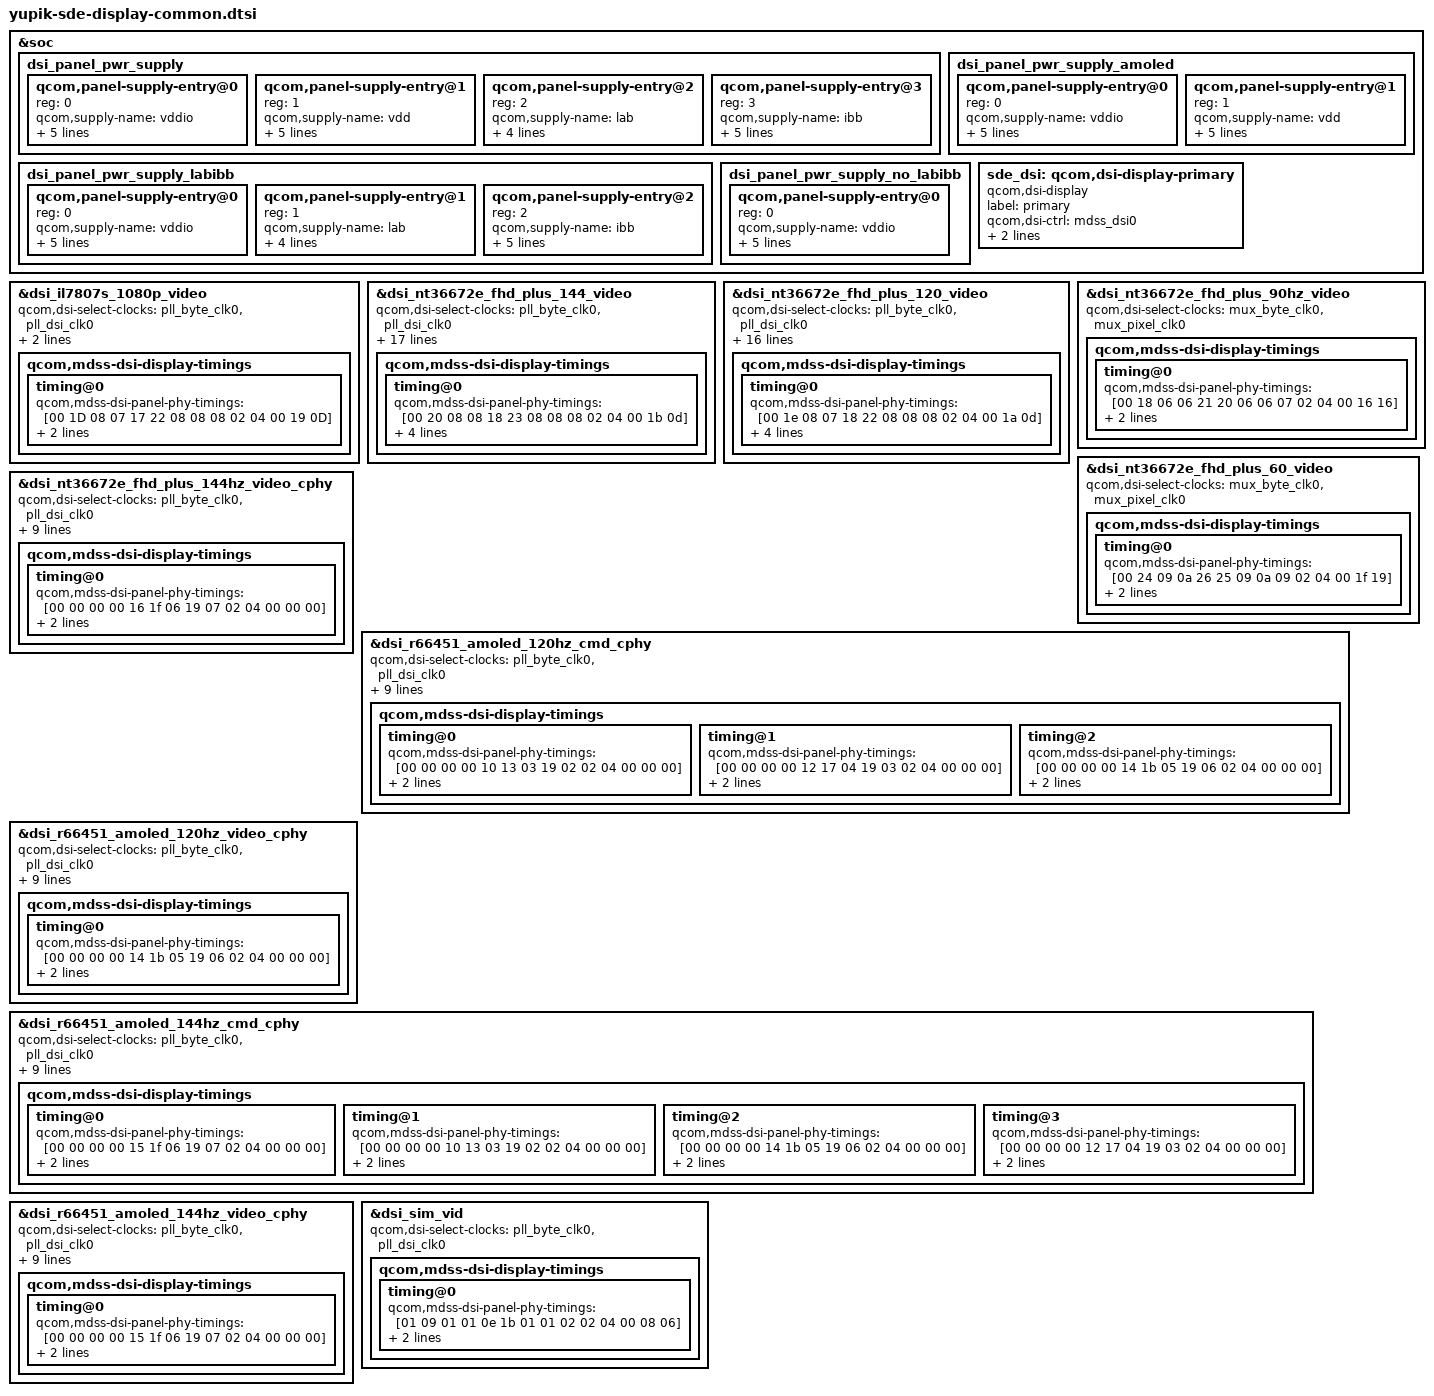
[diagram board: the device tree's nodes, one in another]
// SPDX-License-Identifier: BSD-3-Clause
/*
 * Copyright (c) Qualcomm Technologies, Inc. and/or its subsidiaries.
 */

#include "dsi-panel-nt36672e-fhd-plus-144-video.dtsi"
#include "dsi-panel-nt36672e-fhd-plus-120-video.dtsi"
#include "dsi-panel-nt36672e-fhd-plus-90hz-video.dtsi"
#include "dsi-panel-nt36672e-fhd-plus-60hz-video.dtsi"
#include "dsi-panel-nt36672e-fhd-plus-144hz-video-cphy.dtsi"
#include "dsi-panel-r66451-dsc-fhd-plus-60hz-cmd-cphy.dtsi"
#include "dsi-panel-r66451-dsc-fhd-plus-90hz-cmd-cphy.dtsi"
#include "dsi-panel-r66451-dsc-fhd-plus-120hz-cmd-cphy.dtsi"
#include "dsi-panel-r66451-dsc-fhd-plus-120hz-video-cphy.dtsi"
#include "dsi-panel-r66451-dsc-fhd-plus-144hz-cmd-cphy.dtsi"
#include "dsi-panel-r66451-dsc-fhd-plus-144hz-video-cphy.dtsi"
#include "dsi-panel-sim-video.dtsi"
#include "dsi-panel-ext-bridge-1080p.dtsi"
#include "dsi-panel-il7807s-1080p-video.dtsi"
#include "dsi-panel-ili9881p-720-video.dtsi"
#include "dsi-panel-ext-bridge-4k30p.dtsi"
#include <dt-bindings/clock/qcom,rpmh.h>
#include "yupik-sde-display-pinctrl.dtsi"

&soc {
	dsi_panel_pwr_supply: dsi_panel_pwr_supply {
		#address-cells = <1>;
		#size-cells = <0>;

		qcom,panel-supply-entry@0 {
			reg = <0>;
			qcom,supply-name = "vddio";
			qcom,supply-min-voltage = <1820000>;
			qcom,supply-max-voltage = <1820000>;
			qcom,supply-enable-load = <60700>;
			qcom,supply-disable-load = <80>;
			qcom,supply-post-on-sleep = <20>;
		};

		qcom,panel-supply-entry@1 {
			reg = <1>;
			qcom,supply-name = "vdd";
			qcom,supply-min-voltage = <3000000>;
			qcom,supply-max-voltage = <3000000>;
			qcom,supply-enable-load = <30000>;
			qcom,supply-disable-load = <0>;
			qcom,supply-post-on-sleep = <0>;
		};

		qcom,panel-supply-entry@2 {
			reg = <2>;
			qcom,supply-name = "lab";
			qcom,supply-min-voltage = <4600000>;
			qcom,supply-max-voltage = <6000000>;
			qcom,supply-enable-load = <0>;
			qcom,supply-disable-load = <0>;
		};

		qcom,panel-supply-entry@3 {
			reg = <3>;
			qcom,supply-name = "ibb";
			qcom,supply-min-voltage = <4600000>;
			qcom,supply-max-voltage = <6000000>;
			qcom,supply-enable-load = <0>;
			qcom,supply-disable-load = <0>;
			qcom,supply-post-on-sleep = <20>;
		};
	};

	dsi_panel_pwr_supply_labibb: dsi_panel_pwr_supply_labibb {
		#address-cells = <1>;
		#size-cells = <0>;

		qcom,panel-supply-entry@0 {
			reg = <0>;
			qcom,supply-name = "vddio";
			qcom,supply-min-voltage = <1800000>;
			qcom,supply-max-voltage = <1800000>;
			qcom,supply-enable-load = <62000>;
			qcom,supply-disable-load = <80>;
			qcom,supply-post-on-sleep = <20>;
		};

		qcom,panel-supply-entry@1 {
			reg = <1>;
			qcom,supply-name = "lab";
			qcom,supply-min-voltage = <5600000>;
			qcom,supply-max-voltage = <6000000>;
			qcom,supply-enable-load = <0>;
			qcom,supply-disable-load = <0>;
		};

		qcom,panel-supply-entry@2 {
			reg = <2>;
			qcom,supply-name = "ibb";
			qcom,supply-min-voltage = <5600000>;
			qcom,supply-max-voltage = <6000000>;
			qcom,supply-enable-load = <0>;
			qcom,supply-disable-load = <0>;
			qcom,supply-post-on-sleep = <20>;
		};
	};

	dsi_panel_pwr_supply_amoled: dsi_panel_pwr_supply_amoled {
		#address-cells = <1>;
		#size-cells = <0>;

		qcom,panel-supply-entry@0 {
			reg = <0>;
			qcom,supply-name = "vddio";
			qcom,supply-min-voltage = <1800000>;
			qcom,supply-max-voltage = <1800000>;
			qcom,supply-enable-load = <60700>;
			qcom,supply-disable-load = <80>;
			qcom,supply-post-on-sleep = <20>;
		};

		qcom,panel-supply-entry@1 {
			reg = <1>;
			qcom,supply-name = "vdd";
			qcom,supply-min-voltage = <3000000>;
			qcom,supply-max-voltage = <3000000>;
			qcom,supply-enable-load = <30000>;
			qcom,supply-disable-load = <0>;
			qcom,supply-post-on-sleep = <0>;
		};
	};

	dsi_panel_pwr_supply_no_labibb: dsi_panel_pwr_supply_no_labibb {
		#address-cells = <1>;
		#size-cells = <0>;

		qcom,panel-supply-entry@0 {
			reg = <0>;
			qcom,supply-name = "vddio";
			qcom,supply-min-voltage = <1800000>;
			qcom,supply-max-voltage = <1800000>;
			qcom,supply-enable-load = <62000>;
			qcom,supply-disable-load = <80>;
			qcom,supply-post-on-sleep = <20>;
		};
	};

	sde_dsi: qcom,dsi-display-primary {
		compatible = "qcom,dsi-display";
		label = "primary";

		qcom,dsi-ctrl = <&mdss_dsi0>;
		qcom,dsi-phy = <&mdss_dsi_phy0>;
		qcom,mdp = <&mdss_mdp>;
	};
};

&dsi_il7807s_1080p_video {
	qcom,dsi-select-clocks = "pll_byte_clk0", "pll_dsi_clk0";
	qcom,mdss-dsi-t-clk-post = <0x0d>;
	qcom,mdss-dsi-t-clk-pre = <0x19>;

	qcom,mdss-dsi-display-timings {
		timing@0{
			qcom,mdss-dsi-panel-phy-timings = [00 1D 08 07 17 22 08
			08 08 02 04 00 19 0D];
			qcom,display-topology = <1 0 1>;
			qcom,default-topology-index = <0>;
		};
	};
};

&dsi_nt36672e_fhd_plus_144_video{
        qcom,dsi-select-clocks = "pll_byte_clk0", "pll_dsi_clk0";

        qcom,qsync-enable;
        qcom,mdss-dsi-qsync-min-refresh-rate = <48>;

        qcom,dsi-supported-dfps-list = <144 120 60 48>;
        qcom,mdss-dsi-pan-enable-dynamic-fps;
        qcom,mdss-dsi-pan-fps-update = "dfps_immediate_porch_mode_vfp";

        qcom,dsi-dyn-clk-enable;
        qcom,dsi-dyn-clk-type = "constant-fps-adjust-vfp";

        qcom,esd-check-enabled;
        qcom,mdss-dsi-panel-status-check-mode = "reg_read";
        qcom,mdss-dsi-panel-status-command = [06 01 00 01 00 00 01 0a];
        qcom,mdss-dsi-panel-status-command-state = "dsi_lp_mode";
        qcom,mdss-dsi-panel-status-value = <0x9c>;
        qcom,mdss-dsi-panel-status-read-length = <1>;

        qcom,mdss-dsi-display-timings {
                timing@0 {
                        qcom,mdss-dsi-panel-phy-timings = [00 20 08 08 18 23 08
                                08 08 02 04 00 1b 0d];
                        qcom,display-topology = <1 1 1>;
                        qcom,default-topology-index = <0>;
                        qcom,dsi-dyn-clk-list = <957616128 950966016 954291072>;
                };
        };
};

&dsi_nt36672e_fhd_plus_120_video {
        qcom,dsi-select-clocks = "pll_byte_clk0", "pll_dsi_clk0";

        qcom,qsync-enable;
        qcom,mdss-dsi-qsync-min-refresh-rate = <48>;

        qcom,dsi-supported-dfps-list = <120 60 48>;
        qcom,mdss-dsi-pan-enable-dynamic-fps;
        qcom,mdss-dsi-pan-fps-update = "dfps_immediate_porch_mode_vfp";

        qcom,dsi-dyn-clk-enable;
        qcom,dsi-dyn-clk-type = "constant-fps-adjust-vfp";

        qcom,mdss-dsi-panel-status-check-mode = "reg_read";
        qcom,mdss-dsi-panel-status-command = [06 01 00 01 00 00 01 0a];
        qcom,mdss-dsi-panel-status-command-state = "dsi_lp_mode";
        qcom,mdss-dsi-panel-status-value = <0x9c>;
        qcom,mdss-dsi-panel-status-read-length = <1>;

        qcom,mdss-dsi-display-timings {
                timing@0 {
                        qcom,mdss-dsi-panel-phy-timings = [00 1e 08 07 18 22 08
                                08 08 02 04 00 1a 0d];
                        qcom,display-topology = <1 1 1>;
                        qcom,default-topology-index = <0>;
                        qcom,dsi-dyn-clk-list = <912015360 904415232 908215296>;
                };
        };
};



&dsi_nt36672e_fhd_plus_90hz_video {
	qcom,dsi-select-clocks = "mux_byte_clk0", "mux_pixel_clk0";
	qcom,mdss-dsi-display-timings {
		timing@0 {
			qcom,mdss-dsi-panel-phy-timings = [00 18 06 06 21 20 06
				06 07 02 04 00 16 16];
			qcom,display-topology = <1 1 1>;
			qcom,default-topology-index = <0>;
		};
	};
};

&dsi_nt36672e_fhd_plus_60_video {
	qcom,dsi-select-clocks = "mux_byte_clk0", "mux_pixel_clk0";
	qcom,mdss-dsi-display-timings {
		timing@0 {
			qcom,mdss-dsi-panel-phy-timings = [00 24 09 0a 26 25 09
				0a 09 02 04 00 1f 19];
			qcom,display-topology = <1 0 1>;
			qcom,default-topology-index = <0>;
		};
	};
};


&dsi_nt36672e_fhd_plus_144hz_video_cphy{
        qcom,dsi-select-clocks = "pll_byte_clk0", "pll_dsi_clk0";

        qcom,esd-check-enabled;
        qcom,mdss-dsi-panel-status-check-mode = "reg_read";
        qcom,mdss-dsi-panel-status-command = [06 01 00 01 00 00 01 0a];
        qcom,mdss-dsi-panel-status-command-state = "dsi_lp_mode";
        qcom,mdss-dsi-panel-status-value = <0x9c>;
        qcom,mdss-dsi-panel-status-read-length = <1>;

        qcom,mdss-dsi-display-timings {
                timing@0 {
                        qcom,mdss-dsi-panel-phy-timings = [00 00 00 00 16 1f 06
                                19 07 02 04 00 00 00];
                        qcom,display-topology = <1 1 1>;
                        qcom,default-topology-index = <0>;
                };
        };
};

/*
&dsi_r66451_amoled_60hz_cmd_cphy {
	qcom,dsi-select-clocks = "mux_byte_clk0", "mux_pixel_clk0",
				"cphy_byte_clk0", "cphy_pixel_clk0";
	qcom,dsi-dyn-clk-enable;
	qcom,dsi-dyn-clk-list = <600652800 598150080 595647360>;
	qcom,mdss-dsi-display-timings {
		timing@0 {
			qcom,mdss-dsi-panel-phy-timings = [00 00 00 00 1d 13 03
					19 02 02 04 00 00 00];
			qcom,display-topology = <1 1 1>;
			qcom,default-topology-index = <0>;
		};
	};
};  

&dsi_r66451_amoled_90hz_cmd_cphy {
	qcom,dsi-select-clocks = "mux_byte_clk0", "mux_pixel_clk0",
				"cphy_byte_clk0", "cphy_pixel_clk0";
	qcom,mdss-dsi-display-timings {
		timing@0 {
			qcom,mdss-dsi-panel-phy-timings = [00 00 00 00 1e 17 04
					19 03 02 04 00 00 00];
			qcom,display-topology = <1 1 1>;
			qcom,default-topology-index = <0>;
		};
	};
}; */

&dsi_r66451_amoled_120hz_cmd_cphy {
        qcom,dsi-select-clocks = "pll_byte_clk0", "pll_dsi_clk0";

        qcom,esd-check-enabled;
        qcom,mdss-dsi-panel-status-check-mode = "reg_read";
        qcom,mdss-dsi-panel-status-command = [06 01 00 01 00 00 01 0a];
        qcom,mdss-dsi-panel-status-command-state = "dsi_lp_mode";
        qcom,mdss-dsi-panel-status-value = <0x1c>;
        qcom,mdss-dsi-panel-status-read-length = <1>;

        qcom,mdss-dsi-display-timings {
                timing@0 {
                        qcom,mdss-dsi-panel-phy-timings = [00 00 00 00 10 13 03
                                19 02 02 04 00 00 00];
                        qcom,display-topology = <1 1 1>;
                        qcom,default-topology-index = <0>;
                };

                timing@1 {
                        qcom,mdss-dsi-panel-phy-timings = [00 00 00 00 12 17 04
                                19 03 02 04 00 00 00];
                        qcom,display-topology = <1 1 1>;
                        qcom,default-topology-index = <0>;
                };

                timing@2 {
                        qcom,mdss-dsi-panel-phy-timings = [00 00 00 00 14 1b 05
                                19 06 02 04 00 00 00];
                        qcom,display-topology = <1 1 1>;
                        qcom,default-topology-index = <0>;
                };
        };
};

&dsi_r66451_amoled_120hz_video_cphy {
        qcom,dsi-select-clocks = "pll_byte_clk0", "pll_dsi_clk0";

        qcom,esd-check-enabled;
        qcom,mdss-dsi-panel-status-check-mode = "reg_read";
        qcom,mdss-dsi-panel-status-command = [06 01 00 01 00 00 01 0a];
        qcom,mdss-dsi-panel-status-command-state = "dsi_lp_mode";
        qcom,mdss-dsi-panel-status-value = <0x1c>;
        qcom,mdss-dsi-panel-status-read-length = <1>;

        qcom,mdss-dsi-display-timings {
                timing@0 {
                        qcom,mdss-dsi-panel-phy-timings = [00 00 00 00 14 1b 05
                                19 06 02 04 00 00 00];
                        qcom,display-topology = <1 1 1>;
                        qcom,default-topology-index = <0>;
                };
        };
};

&dsi_r66451_amoled_144hz_cmd_cphy {
        qcom,dsi-select-clocks = "pll_byte_clk0", "pll_dsi_clk0";

        qcom,esd-check-enabled;
        qcom,mdss-dsi-panel-status-check-mode = "reg_read";
        qcom,mdss-dsi-panel-status-command = [06 01 00 01 00 00 01 0a];
        qcom,mdss-dsi-panel-status-command-state = "dsi_lp_mode";
        qcom,mdss-dsi-panel-status-value = <0x1c>;
        qcom,mdss-dsi-panel-status-read-length = <1>;

        qcom,mdss-dsi-display-timings {
                timing@0 {
                        qcom,mdss-dsi-panel-phy-timings = [00 00 00 00 15 1f 06
                                19 07 02 04 00 00 00];
                        qcom,display-topology = <1 1 1>;
                        qcom,default-topology-index = <0>;
                };

                timing@1 {
                        qcom,mdss-dsi-panel-phy-timings = [00 00 00 00 10 13 03
                                19 02 02 04 00 00 00];
                        qcom,display-topology = <1 1 1>;
                        qcom,default-topology-index = <0>;
                };

                timing@2 {
                        qcom,mdss-dsi-panel-phy-timings = [00 00 00 00 14 1b 05
                                19 06 02 04 00 00 00];
                        qcom,display-topology = <1 1 1>;
                        qcom,default-topology-index = <0>;
                };

                timing@3 {
                        qcom,mdss-dsi-panel-phy-timings = [00 00 00 00 12 17 04
                                19 03 02 04 00 00 00];
                        qcom,display-topology = <1 1 1>;
                        qcom,default-topology-index = <0>;
                };
        };
};


&dsi_r66451_amoled_144hz_video_cphy {
        qcom,dsi-select-clocks = "pll_byte_clk0", "pll_dsi_clk0";

        qcom,esd-check-enabled;
        qcom,mdss-dsi-panel-status-check-mode = "reg_read";
        qcom,mdss-dsi-panel-status-command = [06 01 00 01 00 00 01 0a];
        qcom,mdss-dsi-panel-status-command-state = "dsi_lp_mode";
        qcom,mdss-dsi-panel-status-value = <0x1c>;
        qcom,mdss-dsi-panel-status-read-length = <1>;

        qcom,mdss-dsi-display-timings {
        timing@0 {
                        qcom,mdss-dsi-panel-phy-timings = [00 00 00 00 15 1f 06
                                19 07 02 04 00 00 00];
                        qcom,display-topology = <1 1 1>;
                        qcom,default-topology-index = <0>;
                };
        };
};


&dsi_sim_vid {
        qcom,dsi-select-clocks = "pll_byte_clk0", "pll_dsi_clk0";

        qcom,mdss-dsi-display-timings {
                timing@0 {
                        qcom,mdss-dsi-panel-phy-timings = [01 09 01 01 0e 1b 01
                                01 02 02 04 00 08 06];
                        qcom,display-topology = <1 0 1>,
                                                <2 0 1>;
                        qcom,default-topology-index = <0>;
                };
        };
};


/*

&dsi_ext_bridge_1080p {
	qcom,dsi-select-clocks = "mux_byte_clk0", "mux_pixel_clk0",
				"src_byte_clk0", "src_pixel_clk0",
				"shadow_byte_clk0", "shadow_pixel_clk0",
				"xo_byte_clk0", "xo_pixel_clk0";
}; 


&dsi_ili9881p_720p_video {
	qcom,panel-supply-entries = <&dsi_panel_pwr_supply_no_labibb>;
	qcom,mdss-dsi-bl-pmic-control-type = "bl_ctrl_pwm";
	pwms = <&pm8350c_pwm 3 0>;
	qcom,bl-pmic-pwm-period-usecs = <100>;
	qcom,mdss-dsi-bl-min-level = <1>;
	qcom,mdss-dsi-bl-max-level = <4095>;
	qcom,platform-reset-gpio = <&tlmm 43 0>;
	qcom,platform-te-gpio = <&tlmm 80 0>;
	qcom,platform-reset-gpio-always-on;

	qcom,mdss-dsi-t-clk-post = <0x0a>;
	qcom,mdss-dsi-t-clk-pre = <0x12>;
	qcom,dsi-display-active;
	qcom,dsi-select-clocks = "mux_byte_clk0", "mux_pixel_clk0",
				"src_byte_clk0", "src_pixel_clk0",
				"shadow_byte_clk0", "shadow_pixel_clk0";
	qcom,mdss-dsi-display-timings {
		timing@0{
			qcom,mdss-dsi-panel-phy-timings = [00 14 05 05 13 1F 05
							   05 06 02 04 00 12 0A];
			qcom,display-topology = <1 0 1>;
			qcom,default-topology-index = <0>;
		};
	};
};


&dsi_ext_bridge_4k30p {
        qcom,dsi-select-clocks = "mux_byte_clk0", "mux_pixel_clk0",
                                "src_byte_clk0", "src_pixel_clk0",
                                "shadow_byte_clk0", "shadow_pixel_clk0",
				"xo_byte_clk0", "xo_pixel_clk0";
}; */
